# ESP32S31_RADIO register map
Vendor: Espressif; Series: ESP32-S31; File version: 3.52
Registers are 32-bit, read-write, no defined reset value unless marked. A register's access mark holds for its fields unless they carry their own. Offsets are from the block's base; [hi:lo] are bit positions; {n}, {i} and the like mark numbered series.

## BTMAC_BLE_PHY_INIT — ESP32-S31 BTMAC words initialized by the complete BLE PHY register-init function. The function identity is supported by the matching ble_phy.c object layout from the ESP32-C61 ecosystem library, while every address, mask and value below comes only from the ESP32-S31 artifact. Neutral INIT names retain the exact operation without promoting the cross-chip hint to hardware truth.
Base 0x20101400
0x74 WORD_0074_OPAQUE — Opaque: meaning not established. BLE PHY register initialization writes the complete zero image. Inner hardware semantics remain unknown.
  [31:0] BITS_0_31_OPAQUE — Opaque: meaning not established.
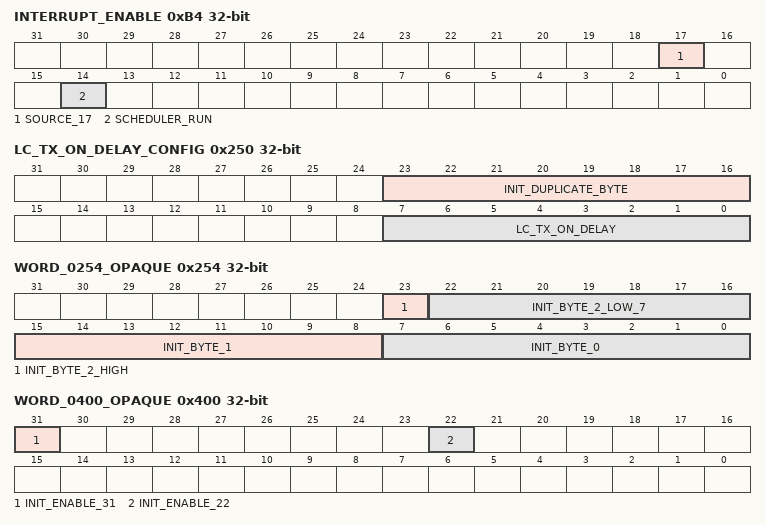
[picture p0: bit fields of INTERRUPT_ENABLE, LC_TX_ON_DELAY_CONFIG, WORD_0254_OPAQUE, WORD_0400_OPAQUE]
0xB4 INTERRUPT_ENABLE — Project-assigned name. BLE base-stack interrupt enable bank. BLE PHY initialization preserves only source 17. The synchronous scheduler-run subscriber clears stale source 14 before enabling it here. All omitted source identities remain unknown.
  [17] SOURCE_17 — Project-assigned name. BLE PHY initialization preserves source 17 while disabling every other interrupt source. Its feature identity remains unknown.
  [14] SCHEDULER_RUN — Project-assigned name. The synchronous base-stack subscriber enables source 14 immediately before the scheduler RUN command.
0xB8 INTERRUPT_CLEAR wo write-1-clears — Project-assigned name. Write-one-to-clear BLE base-stack interrupt bank. Initialization acknowledges every source with an all-ones image; the synchronous scheduler-run subscriber acknowledges source 14 before enabling it.
  [14] SCHEDULER_RUN — Project-assigned name. A one acknowledges stale scheduler-run source 14 before that source is enabled.
0x138 WORD_0138_OPAQUE — Opaque: meaning not established. BLE PHY register initialization writes the finite complete image 0x0000065B.
  [31:0] BITS_0_31_OPAQUE — Opaque: meaning not established.
0x250 LC_TX_ON_DELAY_CONFIG — Project-assigned name. BLE transmit timing configuration. ble_tx_config_check independently prints byte zero as lc_tx_on_delay; BLE PHY initialization writes the same runtime-derived byte image into bytes zero and two.
  [23:16] INIT_DUPLICATE_BYTE — Project-assigned name. BLE PHY initialization receives the same configuration-byte-minus-one image as LC_TX_ON_DELAY. No independent semantic name is claimed.
  [7:0] LC_TX_ON_DELAY — Project-assigned name. Low byte printed as lc_tx_on_delay by complete ble_tx_config_check. BLE PHY initialization stores a configuration byte minus one.
0x254 WORD_0254_OPAQUE — Opaque: meaning not established. BLE PHY initialization replaces the first three bytes with the exact images 0x01, 0x01 and 0xB2.
  [23] INIT_BYTE_2_HIGH — Project-assigned name. The first byte-two clear preserves this bit and the following OR forces it to one.
  [22:16] INIT_BYTE_2_LOW_7 — Project-assigned name.
  [15:8] INIT_BYTE_1 — Project-assigned name.
  [7:0] INIT_BYTE_0 — Project-assigned name.
0x400 WORD_0400_OPAQUE — Opaque: meaning not established. BLE PHY initialization first writes bit 31 as a complete image and then sets bit 22 through a fresh-read RMW.
  [31] INIT_ENABLE_31 — Project-assigned name.
  [22] INIT_ENABLE_22 — Project-assigned name.
0x458 WORD_0458_OPAQUE — Opaque: meaning not established. BLE PHY initialization replaces the upper halfword with the finite image 0x000F.
  [31:16] INIT_HIGH_HALF — Project-assigned name.
0x45C WORD_045C_OPAQUE — Opaque: meaning not established. BLE PHY register initialization writes the finite complete image 8.
  [31:0] BITS_0_31_OPAQUE — Opaque: meaning not established.
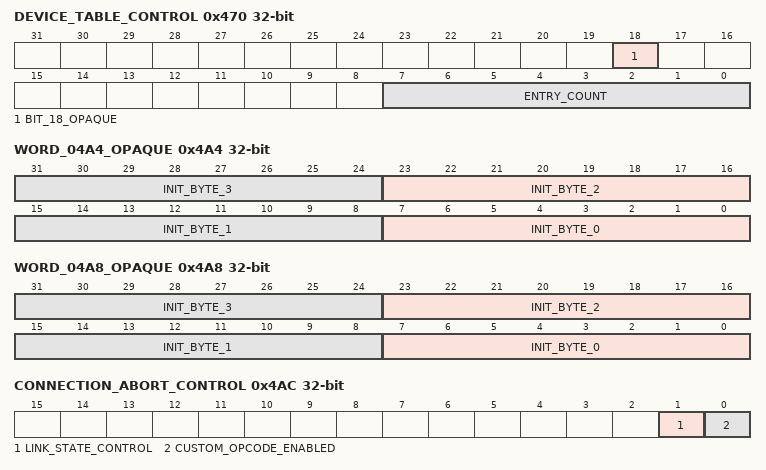
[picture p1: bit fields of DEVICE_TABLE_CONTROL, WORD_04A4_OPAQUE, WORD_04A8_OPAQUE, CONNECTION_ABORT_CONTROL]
0x470 DEVICE_TABLE_CONTROL — Project-assigned name. Device-table control word. Every device-table change rewrites the entry count in the low byte; one complete BLE PHY initialization branch sets bit 18. Both writers preserve the other bits, whose meaning remains unknown.
  [18] BIT_18_OPAQUE — Opaque: meaning not established. The complete BLE PHY initialization body's selected branch sets this positional bit. No independent enable, allowlist, or directed-advertising hardware meaning is proven.
  [7:0] ENTRY_COUNT — Project-assigned name. Number of entries of the Controller-SRAM device table the filter accept list and the resolving list share, valid or not; hardware walks this many entries.
0x474 DEVICE_TABLE_FIRST_ENTRY wo — Project-assigned name. Compressed word address of the first device-table entry. Every device-table change writes it completely with zero in bits 20..31.
  [19:0] COMPRESSED_ADDRESS — Project-assigned name. Controller-SRAM byte address of the first entry shifted right by two, in the twenty-bit compressed link encoding.
0x4A0 WORD_04A0_OPAQUE — Opaque: meaning not established. BLE PHY initialization writes a runtime-derived complete image formed from a linked global address. The destination's hardware meaning remains unknown.
  [31:0] BITS_0_31_OPAQUE — Opaque: meaning not established.
0x4A4 WORD_04A4_OPAQUE — Opaque: meaning not established. BLE PHY register initialization writes four byte images equal to 2.
  [8n+7:8n] INIT_BYTE_{n} (n=0..3) — Project-assigned name.
0x4A8 WORD_04A8_OPAQUE — Opaque: meaning not established. BLE PHY register initialization writes four byte images equal to 2.
  [8n+7:8n] INIT_BYTE_{n} (n=0..3) — Project-assigned name.
0x4AC CONNECTION_ABORT_CONTROL — Project-assigned name. Connection aborted-opcode control. BLE PHY initialization and the default aborted-opcode path write 0x00FF0002, while the custom-opcode path writes 0x00FF0003. Connection link-state refresh independently replaces bit 1 from its two private control flags.
  [1] LINK_STATE_CONTROL — Project-assigned name. The complete connection link-state refresh clears this bit when its second private control flag is set, independently of the first flag, and sets it otherwise. The field selects the connection opcode-abort path; software-authenticated control PDUs require it cleared before RX publication.
  [0] CUSTOM_OPCODE_ENABLED — Project-assigned name.
0x540 WORD_0540_OPAQUE — Opaque: meaning not established. BLE PHY register initialization writes the complete controller-configuration word at offset 0x40, which the pinned configuration defaults to 2000.
  [31:0] BITS_0_31_OPAQUE — Opaque: meaning not established.
0x54C WORD_054C_OPAQUE — Opaque: meaning not established. BLE PHY initialization replaces the low five bits with the finite image 0x12.
  [4:0] INIT_LOW_5 — Project-assigned name.
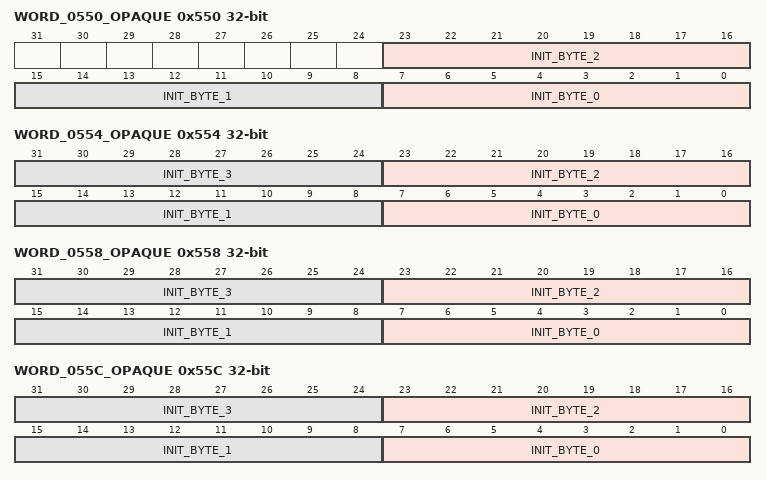
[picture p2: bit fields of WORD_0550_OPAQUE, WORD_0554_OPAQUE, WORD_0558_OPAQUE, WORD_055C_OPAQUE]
0x550 WORD_0550_OPAQUE — Opaque: meaning not established. BLE PHY initialization replaces the low three bytes with 0x03, 0x03 and 0x44.
  [23:16] INIT_BYTE_2 — Project-assigned name.
  [15:8] INIT_BYTE_1 — Project-assigned name.
  [7:0] INIT_BYTE_0 — Project-assigned name.
0x554 WORD_0554_OPAQUE — Opaque: meaning not established. BLE PHY initialization replaces all four bytes with 0x10, 0x10, 0x3C and 0x28.
  [8n+7:8n] INIT_BYTE_{n} (n=0..3) — Project-assigned name.
0x558 WORD_0558_OPAQUE — Opaque: meaning not established. BLE PHY initialization replaces all four bytes with 0x0C, 0x08, 0x0C and 0x0C.
  [8n+7:8n] INIT_BYTE_{n} (n=0..3) — Project-assigned name.
0x55C WORD_055C_OPAQUE — Opaque: meaning not established. BLE PHY initialization replaces all four bytes with 0x08.
  [8n+7:8n] INIT_BYTE_{n} (n=0..3) — Project-assigned name.
